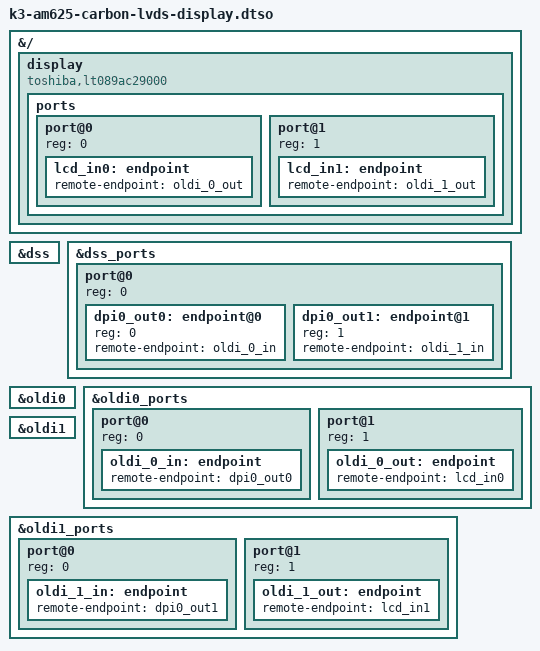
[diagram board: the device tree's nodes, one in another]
// SPDX-License-Identifier: GPL-2.0-only OR MIT
/*
 * LVDS Display for Carbon AM62xx
 *
 * Copyright (C) 2024 Ezurio LLC
 */

/dts-v1/;
/plugin/;

&{/} {
	display {
		compatible = "toshiba,lt089ac29000", "panel-simple"; /* 1280 X 720 */
		ports {
			#address-cells = <1>;
			#size-cells = <0>;

			port@0 {
				reg = <0>;
				lcd_in0: endpoint {
					remote-endpoint = <&oldi_0_out>;
				};
			};

			port@1 {
				reg = <1>;
				lcd_in1: endpoint {
					remote-endpoint = <&oldi_1_out>;
				};
			};
		};
	};
};

&dss {
	status = "okay";
	/* OLDITX ports have no mux on them */
};

&dss_ports {
	#address-cells = <1>;
	#size-cells = <0>;

	/* Video Port 1 Output to OLDI */
	port@0 {
		reg = <0>;
		#address-cells = <1>;
		#size-cells = <0>;

		dpi0_out0: endpoint@0 {
			reg = <0>;
			remote-endpoint = <&oldi_0_in>;
		};

		dpi0_out1: endpoint@1 {
			reg = <1>;
			remote-endpoint = <&oldi_1_in>;
		};
	};
};

&oldi0 {
	status = "okay";
};

&oldi0_ports {
	#address-cells = <1>;
	#size-cells = <0>;

	port@0 {
		reg = <0>; 
		oldi_0_in: endpoint {
			remote-endpoint = <&dpi0_out0>;
		};
	};

	port@1 {
		reg = <1>;
		oldi_0_out: endpoint {
			remote-endpoint = <&lcd_in0>;
		};
	};
};

&oldi1 {
	status = "okay";
};

&oldi1_ports {
	#address-cells = <1>;
	#size-cells = <0>;

	port@0 {
		reg = <0>;
		oldi_1_in: endpoint {
			remote-endpoint = <&dpi0_out1>;
		};
	};

	port@1 {
		reg = <1>;
		oldi_1_out: endpoint {
			remote-endpoint = <&lcd_in1>;
		};
	};
};
